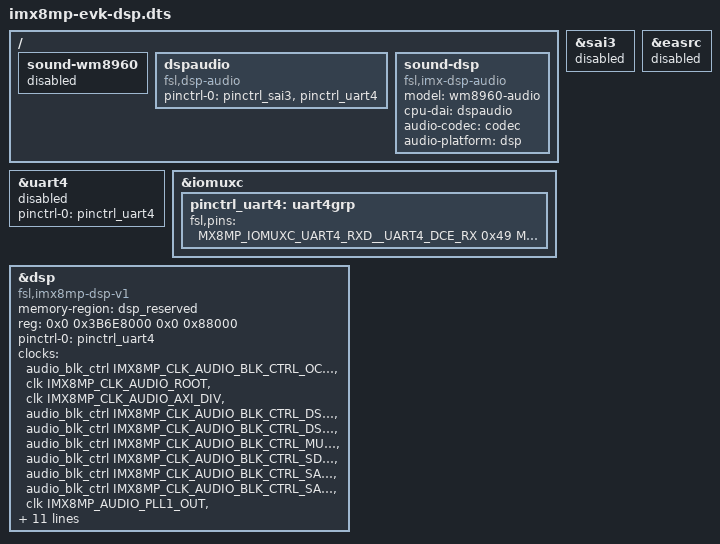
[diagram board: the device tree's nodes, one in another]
// SPDX-License-Identifier: (GPL-2.0+ OR MIT)
/*
 * Copyright 2020 NXP
 */
/dts-v1/;

#include "imx8mp-evk.dts"

/ {
	sound-wm8960 {
		status = "disable";
	};

	dspaudio: dspaudio {
		compatible = "fsl,dsp-audio";
		pinctrl-names = "default";
		pinctrl-0 = <&pinctrl_sai3 &pinctrl_uart4>;
		status = "okay";
	};

	sound-dsp {
		compatible = "fsl,imx-dsp-audio";
		model = "wm8960-audio";
		cpu-dai = <&dspaudio>;
		audio-codec = <&codec>;
		audio-platform = <&dsp>;
	};
};

&sai3 {
	status = "disable";
};

&easrc {
	status = "disable";
};

&uart4 {
	/* console  for debug dsp*/
	pinctrl-names = "default";
	pinctrl-0 = <&pinctrl_uart4>;
	status = "disabled";
};

&iomuxc {
	pinctrl_uart4: uart4grp {
		fsl,pins = <
			MX8MP_IOMUXC_UART4_RXD__UART4_DCE_RX	0x49
			MX8MP_IOMUXC_UART4_TXD__UART4_DCE_TX	0x49
		>;
	};
};

&dsp {
	compatible = "fsl,imx8mp-dsp-v1";
	memory-region = <&dsp_reserved>;
	reg = <0x0 0x3B6E8000 0x0 0x88000>;
	pinctrl-0 = <&pinctrl_uart4>;
	clocks = <&audio_blk_ctrl IMX8MP_CLK_AUDIO_BLK_CTRL_OCRAMA_IPG>,
		<&clk IMX8MP_CLK_AUDIO_ROOT>,
		<&clk IMX8MP_CLK_AUDIO_AXI_DIV>,
		<&audio_blk_ctrl IMX8MP_CLK_AUDIO_BLK_CTRL_DSP_ROOT>,
		<&audio_blk_ctrl IMX8MP_CLK_AUDIO_BLK_CTRL_DSPDBG_ROOT>,
		<&audio_blk_ctrl IMX8MP_CLK_AUDIO_BLK_CTRL_MU2_ROOT>,
		<&audio_blk_ctrl IMX8MP_CLK_AUDIO_BLK_CTRL_SDMA3_ROOT>,
		<&audio_blk_ctrl IMX8MP_CLK_AUDIO_BLK_CTRL_SAI3_IPG>,
		<&audio_blk_ctrl IMX8MP_CLK_AUDIO_BLK_CTRL_SAI3_MCLK1>,
		<&clk IMX8MP_AUDIO_PLL1_OUT>,
		<&clk IMX8MP_AUDIO_PLL2_OUT>,
		<&audio_blk_ctrl IMX8MP_CLK_AUDIO_BLK_CTRL_ASRC_IPG>,
		<&clk IMX8MP_CLK_UART4_ROOT>,
		 <&clk IMX8MP_CLK_UART4_ROOT>;
	clock-names = "ocram", "audio_root", "audio_axi", "core", "debug", "mu2", "sdma_root", "sai_ipg", "sai_mclk", "pll8k", "pll11k",
	"asrc_ipg", "uart_ipg", "uart_per";

	power-domains = <&audiomix_pd>;
	assigned-clocks = <&clk IMX8MP_CLK_SAI3>;
	assigned-clock-parents = <&clk IMX8MP_AUDIO_PLL1_OUT>;
	assigned-clock-rates = <12288000>;

	audio-interface = "sai";
	fsl,dsp-firmware = "imx/dsp/hifi4.bin";
	status = "okay";
};
